# bao1x register map
Vendor: baochip; File version: 1.0
Registers are 32-bit, read-write, reset 0x0 unless marked. A register's access mark holds for its fields unless they carry their own. Offsets are from the block's base; [hi:lo] are bit positions.

## MB_CLIENT
Base 0xE0019000
0x00 WDATA — Write data to outgoing FIFO.
0x04 RDATA — Read data from incoming FIFO.
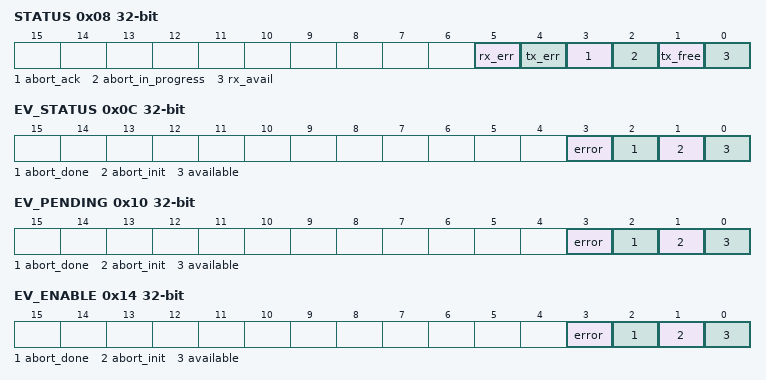
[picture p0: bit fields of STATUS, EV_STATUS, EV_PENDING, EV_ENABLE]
0x08 STATUS
  [5] rx_err — Set if the recipient didn't have data available for a read. Cleared on read.
  [4] tx_err — Set if the recipient was not ready for the data. Cleared on read.
  [3] abort_ack — This bit is set by the peer that acknowledged the incoming abort (the later of the two, in case of an imperfect race condition). The abort response handler should check this bit; if it is set, no new acknowledgement shall be issued. The bit is cleared when an initiator initiates a new abort. The initiator shall also ignore the state of this bit if it is intending to initiate a new abort cycle.
  [2] abort_in_progress — This bit is set if an `aborting` event was initiated and is still in progress.
  [1] tx_free — Tx register can be written
  [0] rx_avail — Rx data is available
0x0C EV_STATUS — Triggers if either `tx_err` or `rx_err` are asserted
  [3] error — Level of the ``error`` event
  [2] abort_done — Level of the ``abort_done`` event
  [1] abort_init — Level of the ``abort_init`` event
  [0] available — Level of the ``available`` event
0x10 EV_PENDING — Triggers if either `tx_err` or `rx_err` are asserted
  [3] error — Triggers if either `tx_err` or `rx_err` are asserted
  [2] abort_done — Triggers when a previously initiated abort is acknowledged by peer
  [1] abort_init — Triggers when abort is asserted by the peer, and there is currently no abort in progress
  [0] available — Triggers when the `done` signal was asserted by the corresponding peer
0x14 EV_ENABLE — Triggers if either `tx_err` or `rx_err` are asserted
  [3] error — Write a ``1`` to enable the ``error`` Event
  [2] abort_done — Write a ``1`` to enable the ``abort_done`` Event
  [1] abort_init — Write a ``1`` to enable the ``abort_init`` Event
  [0] available — Write a ``1`` to enable the ``available`` Event
0x18 CONTROL
  [0] abort — Write `1` to this field to both initiate and acknowledge an abort. Empties both FIFOs, asserts `aborting`, and prevents an interrupt from being generated by an incoming abort request. New reads & writes are ignored until `aborted` is asserted from the peer.
0x1C DONE
  [0] done — Writing a `1` to this field indicates to the corresponding peer that a full packet is done loading. There is no need to clear this register after writing.

## RESETVALUE
Base 0xE001A000
0x00 PC — Latched value for PC on reset

## TICKTIMER
Base 0xE001B000
0x00 CONTROL
  [0] reset — Write a `1` to this bit to reset the count to 0. This bit has priority over all other requests.
0x04 TIME1 — Bits 32-63 of `TICKTIMER_TIME`. Elapsed time in systicks
  [31:0] time
0x08 TIME0 — Bits 0-31 of `TICKTIMER_TIME`.
  [31:0] time
0x0C MSLEEP_TARGET1 — Bits 32-63 of `TICKTIMER_MSLEEP_TARGET`. Target time in 1.0ms ticks
  [31:0] msleep_target
0x10 MSLEEP_TARGET0 — Bits 0-31 of `TICKTIMER_MSLEEP_TARGET`.
  [31:0] msleep_target
0x14 EV_STATUS — This register contains the current raw level of the alarm event trigger. Writes to this register have no effect.
  [0] alarm — Level of the ``alarm`` event
0x18 EV_PENDING — When a alarm event occurs, the corresponding bit will be set in this register. To clear the Event, set the corresponding bit in this register.
  [0] alarm — `1` if a `alarm` event occurred. This Event is **level triggered** when the signal is **high**.
0x1C EV_ENABLE — This register enables the corresponding alarm events. Write a ``0`` to this register to disable individual events.
  [0] alarm — Write a ``1`` to enable the ``alarm`` Event
0x20 CLOCKS_PER_TICK reset 0xC3500 — Clocks per tick, defaults to 800000

## TIMER0
Base 0xE001C000
0x00 LOAD — Load value when Timer is (re-)enabled. In One-Shot mode, the value written to this register specifies the Timer's duration in clock cycles.
0x04 RELOAD — Reload value when Timer reaches ``0``. In Periodic mode, the value written to this register specify the Timer's period in clock cycles.
0x08 EN — Enable flag of the Timer. Set this flag to ``1`` to enable/start the Timer. Set to ``0`` to disable the Timer.
  [0] en
0x0C UPDATE_VALUE — Update trigger for the current countdown value. A write to this register latches the current countdown value to ``value`` register.
  [0] update_value
0x10 VALUE — Latched countdown value. This value is updated by writing to ``update_value``.
0x14 EV_STATUS — This register contains the current raw level of the zero event trigger. Writes to this register have no effect.
  [0] zero — Level of the ``zero`` event
0x18 EV_PENDING — When a zero event occurs, the corresponding bit will be set in this register. To clear the Event, set the corresponding bit in this register.
  [0] zero — `1` if a `zero` event occurred. This Event is triggered on a **falling** edge.
0x1C EV_ENABLE — This register enables the corresponding zero events. Write a ``0`` to this register to disable individual events.
  [0] zero — Write a ``1`` to enable the ``zero`` Event
